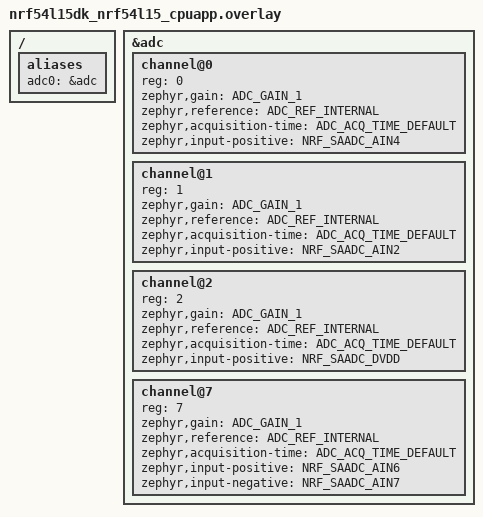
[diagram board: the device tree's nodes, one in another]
/*
 * SPDX-License-Identifier: Apache-2.0
 *
 * Copyright (c) 2024 Nordic Semiconductor ASA
 */

/ {
	aliases {
		adc0 = &adc;
	};
};

&adc {
	#address-cells = <1>;
	#size-cells = <0>;

	channel@0 {
		reg = <0>;
		zephyr,gain = "ADC_GAIN_1";
		zephyr,reference = "ADC_REF_INTERNAL";
		zephyr,acquisition-time = <ADC_ACQ_TIME_DEFAULT>;
		zephyr,input-positive = <NRF_SAADC_AIN4>; /* P1.11 */
	};

	channel@1 {
		reg = <1>;
		zephyr,gain = "ADC_GAIN_1";
		zephyr,reference = "ADC_REF_INTERNAL";
		zephyr,acquisition-time = <ADC_ACQ_TIME_DEFAULT>;
		zephyr,input-positive = <NRF_SAADC_AIN2>; /* P1.06 */
	};

	channel@2 {
		reg = <2>;
		zephyr,gain = "ADC_GAIN_1";
		zephyr,reference = "ADC_REF_INTERNAL";
		zephyr,acquisition-time = <ADC_ACQ_TIME_DEFAULT>;
		zephyr,input-positive = <NRF_SAADC_DVDD>; /* 0.9 V internal */
	};

	channel@7 {
		reg = <7>;
		zephyr,gain = "ADC_GAIN_1";
		zephyr,reference = "ADC_REF_INTERNAL";
		zephyr,acquisition-time = <ADC_ACQ_TIME_DEFAULT>;
		zephyr,input-positive = <NRF_SAADC_AIN6>; /* P1.13 */
		zephyr,input-negative = <NRF_SAADC_AIN7>; /* P1.14 */
	};
};
